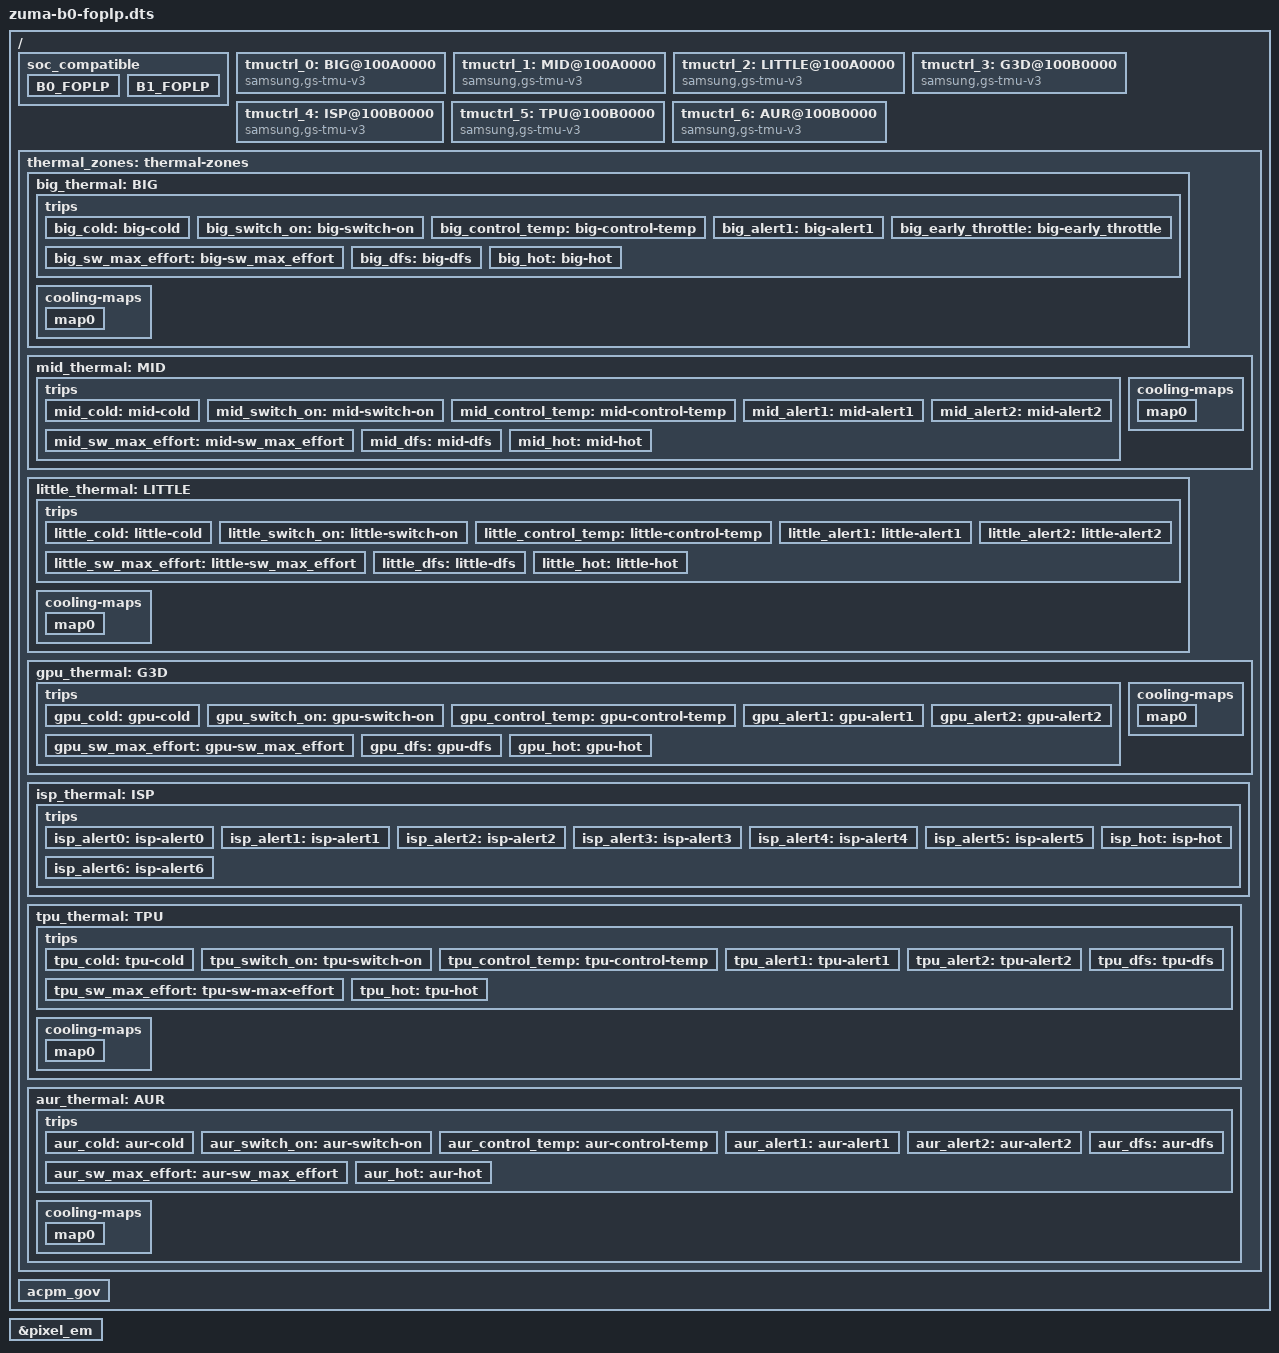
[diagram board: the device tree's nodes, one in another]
// SPDX-License-Identifier: GPL-2.0-only
/*
 * Copyright 2023 Google LLC.
 *
 */

/dts-v1/;
/ {
	/* List of SoCs that this device tree is compatible with */
	soc_compatible {
		B0_FOPLP {
			description = "B0,FOPLP";
			product_id = <0x09865>;
			major = <0x1>;
			minor = <0x0>;
			pkg_mode = <0x0>;
		};
		B1_FOPLP {
			description = "B1,FOPLP";
			product_id = <0x09865>;
			major = <0x1>;
			minor = <0x1>;
			pkg_mode = <0x0>;
		};
	};
};

#include "zuma-b0.dtsi"

/ {

	tmuctrl_0: BIG@100A0000 {
		compatible = "samsung,gs-tmu-v3";
		reg = <0x0 0x100A0000 0x800>;
		interrupts = <GIC_SPI IRQ_TMU_TOP_INTREQ_MISC IRQ_TYPE_LEVEL_HIGH 0>;
		tmu_name = "BIG";
		id = <0>;
		ect_nouse;
		#thermal-sensor-cells = <0>;

		use-pi-thermal;
		polling_delay_on = <25>;
		polling_delay_off = <0>;
		k_po = <30>;
		k_pu = <30>;
		k_i = <50>;
		i_max = <5>;
		integral_cutoff = <10>;
		sustainable_power = <2000>;
		control_temp_step = <1000>; // mC per second
		junction_offset = <0 (-15000) (-15000) (-15000) 0 0 0 0>; // mC

		early_throttle_enable;
		early_throttle_k_p = <50>;
		early_throttle_offset = <10>; // in Celsius

		use-hardlimit-pid;

		tmu_work_affinity = "0-8";

		use-acpm-gov;
		irq_stepwise_gain = <2>;
		timer_stepwise_gain = <1>;
		thermal_pressure_time_window = <100>;

		mapped_cpus = "8";
		pressure_index = <0>;

		use-acpm-mpmm-throttle;
		mpmm_enable = <0x1>;
		mpmm_throttle_level = <0x4>;
		mpmm_clr_throttle_level = <0x6>;
	};

	tmuctrl_1: MID@100A0000 {
		compatible = "samsung,gs-tmu-v3";
		reg = <0x0 0x100A0000 0x800>;
		interrupts = <GIC_SPI IRQ_TMU_TOP_INTREQ_MISC IRQ_TYPE_LEVEL_HIGH 0>;
		tmu_name = "MID";
		id = <1>;
		ect_nouse;
		#thermal-sensor-cells = <0>;

		use-pi-thermal;
		polling_delay_on = <25>;
		polling_delay_off = <0>;
		k_po = <60>;
		k_pu = <60>;
		k_i = <20>;
		i_max = <5>;
		integral_cutoff = <20>;
		sustainable_power = <1000>;
		control_temp_step = <1000>; // mC per second
		junction_offset = <0 (-15000) (-15000) (-15000) 0 0 0 0>; // mC

		tmu_work_affinity = "0-8";

		use-acpm-gov;
		irq_stepwise_gain = <2>;
		timer_stepwise_gain = <1>;
		thermal_pressure_time_window = <100>;

		mapped_cpus = "4-7";
		pressure_index = <1>;

		use-acpm-mpmm-throttle;
		mpmm_enable = <0xF>;
		mpmm_throttle_level = <0x100>;
		mpmm_clr_throttle_level = <0x1AA>;
	};

	tmuctrl_2: LITTLE@100A0000 {
		compatible = "samsung,gs-tmu-v3";
		reg = <0x0 0x100A0000 0x800>;
		interrupts = <GIC_SPI IRQ_TMU_TOP_INTREQ_MISC IRQ_TYPE_LEVEL_HIGH 0>;
		tmu_name = "LITTLE";
		id = <2>;
		ect_nouse;
		#thermal-sensor-cells = <0>;

		use-pi-thermal;
		polling_delay_on = <50>;
		polling_delay_off = <0>;
		k_po = <68>;
		k_pu = <68>;
		k_i = <22>;
		i_max = <5>;
		integral_cutoff = <20>;
		sustainable_power = <200>;
		control_temp_step = <1000>; // mC per second
		junction_offset = <0 (-10000) (-15000) (-15000) 0 0 0 0>; // mC

		tmu_work_affinity = "0-8";

		use-acpm-gov;
		irq_stepwise_gain = <2>;
		timer_stepwise_gain = <1>;
		thermal_pressure_time_window = <100>;

		mapped_cpus = "0-3";
		pressure_index = <2>;

		mpmm_enable = <0x0>;
		mpmm_throttle_level = <0x1AA>;
		mpmm_clr_throttle_level = <0x1AA>;
	};

	tmuctrl_3: G3D@100B0000 {
		compatible = "samsung,gs-tmu-v3";
		reg = <0x0 0x100B0000 0x800>;
		interrupts = <GIC_SPI IRQ_TMU_SUB_INTREQ_MISC IRQ_TYPE_LEVEL_HIGH 0>;
		tmu_name = "G3D";
		id = <3>;
		ect_nouse;
		#thermal-sensor-cells = <0>;

		use-pi-thermal;
		polling_delay_on = <50>;
		polling_delay_off = <0>;
		k_po = <60>;
		k_pu = <60>;
		k_i = <20>;
		i_max = <5>;
		integral_cutoff = <20>;
		sustainable_power = <200>;
		control_temp_step = <1000>; // mC per second
		junction_offset = <0 (-20000) (-20000) (-20000) 0 0 0 0>; // mC

		tmu_work_affinity = "0-8";

		use-acpm-gov;
		irq_stepwise_gain = <2>;
		timer_stepwise_gain = <1>;
	};

	tmuctrl_4: ISP@100B0000 {
		compatible = "samsung,gs-tmu-v3";
		reg = <0x0 0x100B0000 0x800>;
		interrupts = <GIC_SPI IRQ_TMU_SUB_INTREQ_MISC IRQ_TYPE_LEVEL_HIGH 0>;
		tmu_name = "ISP";
		id = <4>;
		ect_nouse;
		#thermal-sensor-cells = <0>;
		junction_offset = <0 (-20000) (-20000) 0 0 0 0 0>; // mC

		tmu_work_affinity = "0-8";
	};

	tmuctrl_5: TPU@100B0000 {
		compatible = "samsung,gs-tmu-v3";
		reg = <0x0 0x100B0000 0x800>;
		interrupts = <GIC_SPI IRQ_TMU_SUB_INTREQ_MISC IRQ_TYPE_LEVEL_HIGH 0>;
		tmu_name = "TPU";
		id = <5>;
		ect_nouse;
		#thermal-sensor-cells = <0>;

		use-pi-thermal;
		polling_delay_on = <50>;
		polling_delay_off = <0>;
		k_po = <1>;
		k_pu = <1>;
		k_i = <1>;
		i_max = <5>;
		integral_cutoff = <20>;
		sustainable_power = <200>;
		control_temp_step = <1000>; // mC per second
		junction_offset = <0 (-20000) (-20000) 0 0 0 0 0>; // mC

		tmu_work_affinity = "0-8";

		use-acpm-gov;
		irq_stepwise_gain = <2>;
		timer_stepwise_gain = <1>;
	};

	tmuctrl_6: AUR@100B0000 {
		compatible = "samsung,gs-tmu-v3";
		reg = <0x0 0x100B0000 0x800>;
		interrupts = <GIC_SPI IRQ_TMU_SUB_INTREQ_MISC IRQ_TYPE_LEVEL_HIGH 0>;
		tmu_name = "AUR";
		id = <6>;
		ect_nouse;
		#thermal-sensor-cells = <0>;
		tmu_work_affinity = "0-8";
		polling_delay_on = <50>;
		junction_offset = <0 (-20000) (-20000) (-20000) 0 0 0 0>; // mC

		use-acpm-gov;
		irq_stepwise_gain = <2>;
		timer_stepwise_gain = <1>;
	};

	thermal_zones: thermal-zones {
		big_thermal: BIG {
			zone_name  = "BIG_THERMAL";
			polling-delay-passive = <0>;
			polling-delay = <0>;
			thermal-sensors = <&tmuctrl_0>;

			trips {
				big_cold: big-cold {
					temperature = <20000>; /* millicelsius */
					hysteresis = <5000>; /* millicelsius */
					type = "active";
				};
				big_switch_on: big-switch-on {
					temperature = <75000>; /* millicelsius */
					hysteresis = <5000>; /* millicelsius */
					type = "active";
				};
				big_control_temp: big-control-temp {
					temperature = <95000>; /* millicelsius */
					hysteresis = <5000>; /* millicelsius */
					type = "passive";
				};
				big_alert1: big-alert1 {
					temperature = <98000>; /* millicelsius */
					hysteresis = <98000>; /* 98C to avoid falling edge irq */
					type = "active";
				};
				big_early_throttle: big-early_throttle {
					temperature = <85000>; /* millicelsius */
					hysteresis = <5000>; /* millicelsius */
					type = "active";
				};
				big_sw_max_effort: big-sw_max_effort {
					temperature = <102000>; /* millicelsius */
					hysteresis = <2000>; /* millicelsius */
					type = "active";
				};
				big_dfs: big-dfs {
					temperature = <105000>; /* millicelsius */
					hysteresis = <5000>; /* millicelsius */
					type = "active";
				};
				big_hot: big-hot {
					temperature = <115000>; /* millicelsius */
					hysteresis = <3000>; /* millicelsius */
					type = "hot";
				};
			};
			cooling-maps {
				map0 {
					trip = <&big_control_temp>;
					cooling-device = <&cpufreq_domain2 0 0>;
				};
			};
		};
		mid_thermal: MID {
			zone_name  = "MID_THERMAL";
			polling-delay-passive = <0>;
			polling-delay = <0>;
			thermal-sensors = <&tmuctrl_1>;

			trips {
				mid_cold: mid-cold {
					temperature = <20000>; /* millicelsius */
					hysteresis = <5000>; /* millicelsius */
					type = "active";
				};
				mid_switch_on: mid-switch-on {
					temperature = <75000>; /* millicelsius */
					hysteresis = <5000>; /* millicelsius */
					type = "active";
				};
				mid_control_temp: mid-control-temp {
					temperature = <95000>; /* millicelsius */
					hysteresis = <5000>; /* millicelsius */
					type = "passive";
				};
				mid_alert1: mid-alert1 {
					temperature = <98000>; /* millicelsius */
					hysteresis = <98000>; /* 98C to avoid falling edge irq */
					type = "active";
				};
				mid_alert2: mid-alert2 {
					temperature = <100000>; /* millicelsius */
					hysteresis = <5000>; /* millicelsius */
					type = "passive";
				};
				mid_sw_max_effort: mid-sw_max_effort {
					temperature = <102000>; /* millicelsius */
					hysteresis = <2000>; /* millicelsius */
					type = "active";
				};
				mid_dfs: mid-dfs {
					temperature = <105000>; /* millicelsius */
					hysteresis = <5000>; /* millicelsius */
					type = "active";
				};
				mid_hot: mid-hot {
					temperature = <115000>; /* millicelsius */
					hysteresis = <3000>; /* millicelsius */
					type = "hot";
				};
			};
			cooling-maps {
				map0 {
				     trip = <&mid_control_temp>;
				     cooling-device = <&cpufreq_domain1 0 0>;
			       };
			};
		};
		little_thermal: LITTLE {
			zone_name  = "LITTLE_THERMAL";
			polling-delay-passive = <0>;
			polling-delay = <0>;
			thermal-sensors = <&tmuctrl_2>;

			trips {
				little_cold: little-cold {
					temperature = <20000>; /* millicelsius */
					hysteresis = <5000>; /* millicelsius */
					type = "active";
				};
				little_switch_on: little-switch-on {
					temperature = <75000>; /* millicelsius */
					hysteresis = <5000>; /* millicelsius */
					type = "active";
				};
				little_control_temp: little-control-temp {
					temperature = <100000>; /* millicelsius */
					hysteresis = <5000>; /* millicelsius */
					type = "passive";
				};
				little_alert1: little-alert1 {
					temperature = <102000>; /* millicelsius */
					hysteresis = <102000>; /* 102C to avoid falling edge irq */
					type = "active";
				};
				little_alert2: little-alert2 {
					temperature = <103000>; /* millicelsius */
					hysteresis = <1000>; /* millicelsius */
					type = "passive";
				};
				little_sw_max_effort: little-sw_max_effort {
					temperature = <104000>; /* millicelsius */
					hysteresis = <1000>; /* millicelsius */
					type = "passive";
				};
				little_dfs: little-dfs {
					temperature = <105000>; /* millicelsius */
					hysteresis = <5000>; /* millicelsius */
					type = "active";
				};
				little_hot: little-hot {
					temperature = <115000>; /* millicelsius */
					hysteresis = <3000>; /* millicelsius */
					type = "hot";
				};
			};
			cooling-maps {
				map0 {
				     trip = <&little_control_temp>;
				     cooling-device = <&cpufreq_domain0 0 0>;
				};
			};
		};
		gpu_thermal: G3D {
			zone_name  = "G3D_THERMAL";
			polling-delay-passive = <0>;
			polling-delay = <0>;
			thermal-sensors = <&tmuctrl_3>;

			trips {
				gpu_cold: gpu-cold {
					temperature = <20000>; /* millicelsius */
					hysteresis = <5000>; /* millicelsius */
					type = "active";
				};
				gpu_switch_on: gpu-switch-on {
					temperature = <80000>; /* millicelsius */
					hysteresis = <5000>; /* millicelsius */
					type = "active";
				};
				gpu_control_temp: gpu-control-temp {
					temperature = <100000>; /* millicelsius */
					hysteresis = <5000>; /* millicelsius */
					type = "passive";
				};
				gpu_alert1: gpu-alert1 {
					temperature = <102000>; /* millicelsius */
					hysteresis = <4000>; /* millicelsius */
					type = "passive";
				};
				gpu_alert2: gpu-alert2 {
					temperature = <103000>; /* millicelsius */
					hysteresis = <103000>; /* 103C to avoid falling edge irq */
					type = "active";
				};
				gpu_sw_max_effort: gpu-sw_max_effort {
					temperature = <107000>; /* millicelsius */
					hysteresis = <2000>; /* millicelsius */
					type = "active";
				};
				gpu_dfs: gpu-dfs {
					temperature = <108000>; /* millicelsius */
					hysteresis = <5000>; /* millicelsius */
					type = "active";
				};
				gpu_hot: gpu-hot {
					temperature = <115000>; /* millicelsius */
					hysteresis = <3000>; /* millicelsius */
					type = "hot";
				};
			};
			cooling-maps {
				map0 {
					trip = <&gpu_control_temp>;
					cooling-device = <&mali
						THERMAL_NO_LIMIT
						THERMAL_NO_LIMIT>;
				};
			};
		};
		isp_thermal: ISP {
			zone_name  = "ISP_THERMAL";
			polling-delay-passive = <0>;
			polling-delay = <0>;
			thermal-sensors = <&tmuctrl_4>;

			trips {
				isp_alert0: isp-alert0 {
					temperature = <20000>; /* millicelsius */
					hysteresis = <5000>; /* millicelsius */
					type = "active";
				};
				isp_alert1: isp-alert1 {
					temperature = <80000>; /* millicelsius */
					hysteresis = <5000>; /* millicelsius */
					type = "passive";
				};
				isp_alert2: isp-alert2 {
					temperature = <100000>; /* millicelsius */
					hysteresis = <5000>; /* millicelsius */
					type = "passive";
				};
				isp_alert3: isp-alert3 {
					temperature = <102000>; /* millicelsius */
					hysteresis = <4000>; /* millicelsius */
					type = "passive";
				};
				isp_alert4: isp-alert4 {
					temperature = <103000>; /* millicelsius */
					hysteresis = <103000>; /* 103C to avoid falling edge irq */
					type = "passive";
				};
				isp_alert5: isp-alert5 {
					temperature = <107000>; /* millicelsius */
					hysteresis = <107000>; /* 107C to avoid falling edge irq */
					type = "passive";
				};
				isp_alert6: isp-alert6 {
					temperature = <108000>; /* millicelsius */
					hysteresis = <108000>; /* 108C to avoid falling edge irq */
					type = "passive";
				};
				isp_hot: isp-hot {
					temperature = <115000>; /* millicelsius */
					hysteresis = <3000>; /* millicelsius */
					type = "hot";
				};
			};
		};
		tpu_thermal: TPU {
			zone_name  = "TPU_THERMAL";
			polling-delay-passive = <0>;
			polling-delay = <0>;
			thermal-sensors = <&tmuctrl_5>;

			trips {
				tpu_cold: tpu-cold {
					temperature = <20000>; /* millicelsius */
					hysteresis = <5000>; /* millicelsius */
					type = "active";
				};
				tpu_switch_on: tpu-switch-on {
					temperature = <80000>; /* millicelsius */
					hysteresis = <5000>; /* millicelsius */
					type = "active";
				};
				tpu_control_temp: tpu-control-temp {
					temperature = <100000>; /* millicelsius */
					hysteresis = <5000>; /* millicelsius */
					type = "passive";
				};
				tpu_alert1: tpu-alert1 {
					temperature = <102000>; /* millicelsius */
					hysteresis = <4000>; /* millicelsius */
					type = "passive";
				};
				tpu_alert2: tpu-alert2 {
					temperature = <103000>; /* millicelsius */
					hysteresis = <103000>; /* 103C to avoid falling edge irq */
					type = "active";
				};
				tpu_sw_max_effort: tpu-sw-max-effort {
					temperature = <107000>; /* millicelsius */
					hysteresis = <2000>; /* millicelsius */
					type = "active";
				};
				tpu_dfs: tpu-dfs {
					temperature = <108000>; /* millicelsius */
					hysteresis = <5000>; /* millicelsius */
					type = "active";
				};
				tpu_hot: tpu-hot {
					temperature = <115000>; /* millicelsius */
					hysteresis = <3000>; /* millicelsius */
					type = "hot";
				};
			};
			cooling-maps {
				map0 {
					trip = <&tpu_control_temp>;
					cooling-device = <&tpu_cooling 0 0>;
				};
			};
		};
		aur_thermal: AUR {
			zone_name  = "AUR_THERMAL";
			polling-delay-passive = <0>;
			polling-delay = <0>;
			thermal-sensors = <&tmuctrl_6>;

			trips {
				aur_cold: aur-cold {
					temperature = <20000>; /* millicelsius */
					hysteresis = <5000>; /* millicelsius */
					type = "active";
				};
				aur_switch_on: aur-switch-on {
					temperature = <80000>; /* millicelsius */
					hysteresis = <5000>; /* millicelsius */
					type = "active";
				};
				aur_control_temp: aur-control-temp {
					temperature = <100000>; /* millicelsius */
					hysteresis = <5000>; /* millicelsius */
					type = "passive";
				};
				aur_alert1: aur-alert1 {
					temperature = <102000>; /* millicelsius */
					hysteresis = <4000>; /* millicelsius */
					type = "passive";
				};
				aur_alert2: aur-alert2 {
					temperature = <103000>; /* millicelsius */
					hysteresis = <103000>; /* 103C to avoid falling edge irq */
					type = "active";
				};
				aur_sw_max_effort: aur-sw_max_effort {
					temperature = <107000>; /* millicelsius */
					hysteresis = <2000>; /* millicelsius */
					type = "active";
				};
				aur_dfs: aur-dfs {
					temperature = <108000>; /* millicelsius */
					hysteresis = <5000>; /* millicelsius */
					type = "active";
				};
				aur_hot: aur-hot {
					temperature = <115000>; /* millicelsius */
					hysteresis = <3000>; /* millicelsius */
					type = "hot";
				};
			};
			cooling-maps {
				map0 {
					trip = <&aur_control_temp>;
					cooling-device = <&gxp_cooling 0 0>;
				};
			};
		};
	};

	acpm_gov {
		thermal_pressure_polling_delay_on = <100>;
		thermal_pressure_polling_delay_off = <0>;

		work_affinity = "0-8";
	};
};

&pixel_em {
	profiles =
		"default
			cpu0 {
			324000 35 11000
			610000 65 12000
			820000 88 19000
			955000 102 25000
			1098000 118 31000
			1197000 128 37000
			1328000 142 45000
			1425000 153 57000
			1548000 166 155000
			1704000 182 195000
			}
			cpu4 {
			402000 123 59000
			578000 177 85000
			697000 213 106000
			712000 218 114000
			910000 279 156000
			1065000 326 208000
			1221000 374 266000
			1328000 406 320000
			1418000 434 368000
			1572000 481 449000
			1836000 562 638000
			1945000 595 804000
			2130000 652 1042000
			2245000 687 1272000
			2367000 725 1514000
			}
			cpu8 {
			500000 176 116000
			880000 309 213000
			1164000 409 321000
			1298000 456 391000
			1557000 547 535000
			1745000 613 675000
			1885000 662 784000
			2049000 720 1034000
			2147000 754 1145000
			2294000 806 1363000
			2363000 830 1533000
			2556000 898 1911000
			2687000 944 2415000
			2850000 1002 3175000
			2914000 1024 3714000
			}
		",
		"cam1
			cpu0 {
			324000 40 5000
			610000 80 17000
			820000 110 26000
			955000 129 32000
			1098000 150 38000
			1197000 164 43000
			1328000 183 56000
			1425000 197 66000
			1548000 214 79000
			1704000 236 96000
			}
			cpu4 {
			402000 100 33000
			578000 168 42000
			697000 215 47000
			712000 221 48000
			910000 298 59000
			1065000 358 67000
			1221000 419 69000
			1328000 461 84000
			1418000 496 93000
			1572000 557 102000
			1836000 660 127000
			1945000 702 142000
			2130000 775 178000
			2245000 819 203000
			2367000 867 237000
			}
			cpu8 {
			500000 340 90000
			880000 587 144000
			1164000 662 194000
			1298000 696 226000
			1557000 760 288000
			1745000 806 348000
			1885000 838 393000
			2049000 865 446000
			2147000 881 521000
			2294000 905 635000
			2363000 916 688000
			2556000 948 837000
			2687000 970 939000
			2850000 989 1000000
			2914000 1007 1060000
			}
		",
		"cam2
			cpu0 {
			324000 21 6000
			610000 40 12000
			820000 54 19000
			955000 63 25000
			1098000 72 31000
			1197000 78 37000
			1328000 87 45000
			1425000 93 57000
			1548000 102 66000
			1704000 112 82000
			}
			cpu4 {
			402000 127 54000
			578000 182 83000
			697000 220 105000
			712000 224 112000
			910000 287 157000
			1065000 335 213000
			1221000 385 269000
			1328000 418 321000
			1418000 447 375000
			1572000 495 453000
			1836000 578 641000
			1945000 613 795000
			2130000 671 986000
			2245000 707 1165000
			2367000 746 1385000
			}
			cpu8 {
			500000 174 96000
			880000 306 196000
			1164000 405 297000
			1298000 452 368000
			1557000 542 516000
			1745000 607 647000
			1885000 656 762000
			2049000 713 946000
			2147000 747 1055000
			2294000 798 1254000
			2363000 822 1407000
			2556000 889 1698000
			2687000 935 2034000
			2850000 992 2521000
			2914000 1014 2851000
			}
		",
		"cam3
			cpu0 {
			324000 33 24000
			610000 63 39000
			820000 84 56000
			955000 100 73000
			1098000 113 86000
			1197000 123 98000
			1328000 136 116000
			1425000 152 141000
			1548000 159 158000
			1704000 175 198000
			}
			cpu4 {
			402000 118 56000
			578000 170 84000
			697000 205 105000
			712000 212 107000
			910000 268 148000
			1065000 318 201000
			1221000 359 251000
			1328000 405 304000
			1418000 439 356000
			1572000 456 405000
			1836000 540 596000
			1945000 588 743000
			2130000 629 930000
			2245000 661 1122000
			2367000 692 1314000
			}
			cpu8 {
			500000 171 121000
			880000 288 225000
			1164000 399 342000
			1298000 443 415000
			1557000 507 544000
			1745000 571 682000
			1885000 609 765000
			2049000 680 983000
			2147000 714 1134000
			2294000 748 1322000
			2363000 794 1481000
			2556000 850 1883000
			2687000 923 2377000
			2850000 972 2882000
			2914000 989 3465000
			}
		";
		idle_energy =
			"
			cpu0 {
			324000 1600
			610000 1600
			820000 1600
			955000 1600
			1098000 3200
			1197000 3200
			1328000 3200
			1425000 3200
			1548000 3200
			1704000 3200
			}
			cpu4 {
			402000 8000
			578000 8000
			697000 8000
			712000 9600
			910000 11200
			1065000 12800
			1221000 12800
			1328000 14400
			1418000 16000
			1572000 17600
			1836000 22400
			1945000 25600
			2130000 33600
			2245000 40000
			2367000 46400
			}
			cpu8 {
			500000 24000
			880000 28800
			1164000 33600
			1298000 36800
			1557000 43200
			1745000 48000
			1885000 52800
			2049000 64000
			2147000 72000
			2294000 83200
			2363000 89600
			2556000 136000
			2687000 168000
			2850000 196800
			2914000 224000
			}
			";
};
